# MM32F3270 register map
File version: 3.01
CPU: CM3 r2p1, selectable endian, MPU, no FPU, 3 interrupt priority bits
Registers are 32-bit, read-write, reset 0x0 unless marked. A register's access mark holds for its fields unless they carry their own. Offsets are from the block's base; [hi:lo] are bit positions; {n}, {i} and the like mark numbered series; 'fields as' and 'values as' point back to an identical list.

## DBG — Debug support
Base 0x40007080
0x00 IDCODE ro — Device ID code
  [31:0] DEV_ID — Device identifier
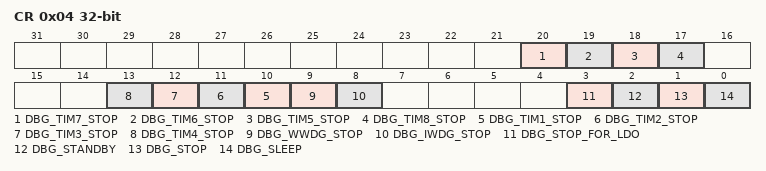
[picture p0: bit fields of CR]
0x04 CR wo — Control Register
  [20] DBG_TIM7_STOP — TIM7 counter stopped when core is halted
  [19] DBG_TIM6_STOP — TIM6 counter stopped when core is halted
  [18] DBG_TIM5_STOP — TIM5 counter stopped when core is halted
  [17] DBG_TIM8_STOP — TIM8 counter stopped when core is halted
  [n+9] DBG_TIM{n}_STOP (n=1..4) — TIM{n} counter stopped when core is halted
  [9] DBG_WWDG_STOP — Debug window watchdog stopped when core is halted
  [8] DBG_IWDG_STOP — Debug independent watchdog stopped when core is hatled
  [3] DBG_STOP_FOR_LDO — Debug Stop mode for Ldo
  [2] DBG_STANDBY — Debug Standby mode
  [1] DBG_STOP — Debug Stop mode
  [0] DBG_SLEEP — Debug Sleep mode

## DEVICE
Base 0x1FFFF7E8
0x00 UID1 16-bit ro — Unique product indentification register 1
  [15:0] U_ID — 15:0 unique ID bits
0x02 UID2 16-bit ro — Unique product indentification register 2
  [15:0] U_ID — 31:16 unique ID bits
0x04 UID3 ro — Unique product indentification register 3
  [31:0] U_ID — 63:32 unique ID bits
0x08 UID4 ro — Unique product indentification register 4
  [31:0] U_ID — 95:64 unique ID bits

## DMA1 — DMA1 controller
Base 0x40020000
Same registers: DMA2 0x40020400
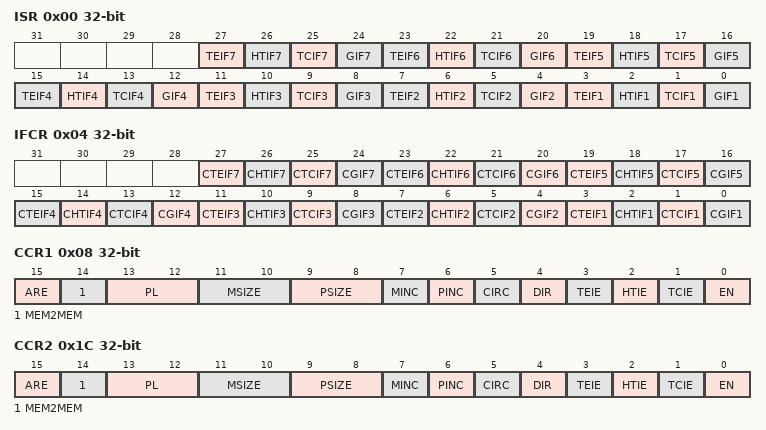
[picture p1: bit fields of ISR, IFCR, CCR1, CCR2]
0x00 ISR ro — Interrupt status register
  [4n-1] TEIF{n} (n=1..7) — channel {n} transfer error flag
  [4n-2] HTIF{n} (n=1..7) — channel {n} half transfer flag
  [4n-3] TCIF{n} (n=1..7) — channel {n} transfer complete flag
  [4n-4] GIF{n} (n=1..7) — channel {n} global interrupt flag
0x04 IFCR wo — Interrupt flag clear register
  [4n-1] CTEIF{n} (n=1..7) — channel {n} transfer error clear
  [4n-2] CHTIF{n} (n=1..7) — channel {n} half transfer clear
  [4n-3] CTCIF{n} (n=1..7) — channel {n} transfer complete clear
  [4n-4] CGIF{n} (n=1..7) — channel {n} global interrupt clear
0x08 CCR1 — Channel 1 configuration register
  [15] ARE — Auto reload
  [14] MEM2MEM — Memory to memory mode
  [13:12] PL — Channel priority level
  [11:10] MSIZE — Memory size
  [9:8] PSIZE — Peripheral size
  [7] MINC — Memory increment mode
  [6] PINC — Peripheral increment mode
  [5] CIRC — Circular mode
  [4] DIR — Data transfer direction
  [3] TEIE — Transfer error interrupt enable
  [2] HTIE — Half transfer interrupt enable
  [1] TCIE — Transfer complete interrupt enable
  [0] EN — Channel enable
0x0C CNDTR1 — Channel 1 number of data register
  [15:0] NDT — Number of data to transfer
0x10 CPAR1 — Channel 1 peripheral address register
  [31:0] PA — Peripheral address
{0x0+0x14*i} CMAR{i} (i=1..7) — Channel {i} memory address register
  [31:0] MA — Memory address
0x1C CCR2 — Channel 2 configuration register
  fields as CCR1
0x20 CNDTR2 — Channel 2 number of data register
  [15:0] NDT — Number of data to transfer
0x24 CPAR2 — Channel 2 peripheral address register
  [31:0] PA — Peripheral address
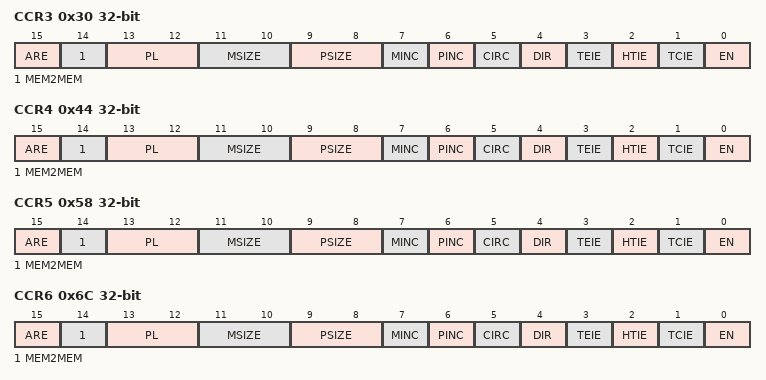
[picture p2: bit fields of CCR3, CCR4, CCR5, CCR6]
0x30 CCR3 — Channel 3 configuration register
  fields as CCR1
0x34 CNDTR3 — Channel 3 number of data register
  [15:0] NDT — Number of data to transfer
0x38 CPAR3 — Channel 3 peripheral address register
  [31:0] PA — Peripheral address
0x44 CCR4 — Channel 4 configuration register
  fields as CCR1
0x48 CNDTR4 — Channel 4 number of data register
  [15:0] NDT — Number of data to transfer
0x4C CPAR4 — Channel 4 peripheral address register
  [31:0] PA — Peripheral address
0x58 CCR5 — Channel 5 configuration register
  fields as CCR1
0x5C CNDTR5 — Channel 5 number of data register
  [15:0] NDT — Number of data to transfer
0x60 CPAR5 — Channel 5 peripheral address register
  [31:0] PA — Peripheral address
0x6C CCR6 — Channel 6 configuration register
  fields as CCR1
0x70 CNDTR6 — Channel 6 number of data register
  [15:0] NDT — Number of data to transfer
0x74 CPAR6 — Channel 6 peripheral address register
  [31:0] PA — Peripheral address
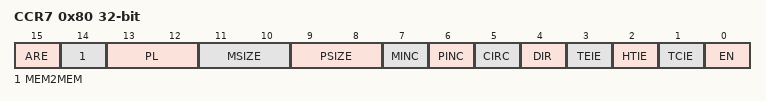
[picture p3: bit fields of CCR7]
0x80 CCR7 — Channel 7 configuration register
  fields as CCR1
0x84 CNDTR7 — Channel 7 number of data register
  [15:0] NDT — Number of data to transfer
0x88 CPAR7 — Channel 7 peripheral address register
  [31:0] PA — Peripheral address
